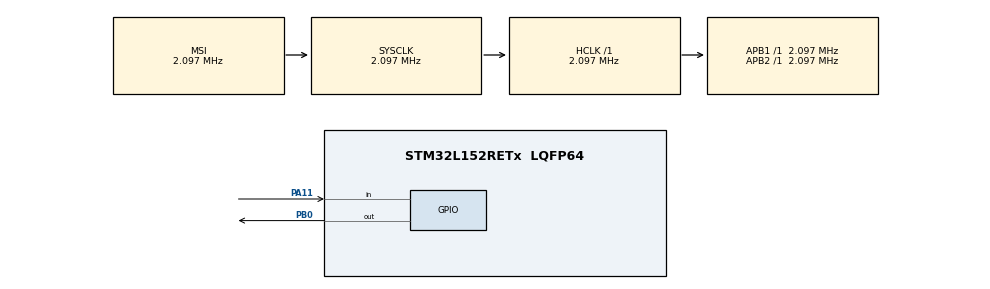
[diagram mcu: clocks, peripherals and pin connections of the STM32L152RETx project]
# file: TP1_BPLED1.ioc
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Mcu.Family=STM32L1
Mcu.Name=STM32L152RETx
Mcu.Package=LQFP64
NVIC.PriorityGroup=NVIC_PRIORITYGROUP_4
PA11.Signal=GPIO_Input
PB0.GPIO_ModeDefaultOutputPP=GPIO_MODE_OUTPUT_PP
PB0.Signal=GPIO_Output
ProjectManager.HeapSize=0x200
ProjectManager.StackSize=0x400
ProjectManager.TargetToolchain=STM32CubeIDE
RCC.AHBFreq_Value=2097000
RCC.APB1Freq_Value=2097000
RCC.APB2Freq_Value=2097000
RCC.HSE_VALUE=24000000
RCC.HSI_VALUE=16000000
RCC.LSE_VALUE=32768
RCC.MSI_VALUE=2097000
RCC.SYSCLKFreq_VALUE=2097000
RCC.VCOOutputFreq_Value=48000000
board=custom

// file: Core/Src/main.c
/* USER CODE BEGIN Header */
/**
  ******************************************************************************
  * @file           : main.c
  * @brief          : Main program body
  ******************************************************************************
  * @attention
  *
  * Copyright (c) 2025 STMicroelectronics.
  * All rights reserved.
  *
  * This software is licensed under terms that can be found in the LICENSE file
  * in the root directory of this software component.
  * If no LICENSE file comes with this software, it is provided AS-IS.
  *
  ******************************************************************************
  */
/* USER CODE END Header */
#include "main.h"

/* USER CODE BEGIN PD */

//#define V1
#define V2

/* USER CODE END PD */

void SystemClock_Config(void);
static void MX_GPIO_Init(void);
/* USER CODE BEGIN PFP */
void init_ports_LED(void);
void init_ports_BP(void);
void allume_LED(void);
void eteint_LED(void);
/* USER CODE END PFP */

/* USER CODE BEGIN 0 */
void init_ports_LED(void) {
	GPIOB->ODR |= 1<<0;
}

void init_ports_BP(void) {
	GPIOA->MODER &= ~(1<<11);
}

void allume_LED(void) {
	GPIOB->ODR |= (1<<0);
}

void eteint_LED(void) {
	GPIOB->ODR &= ~(1<<0);
}
/* USER CODE END 0 */

int main(void)
{

  /* MCU Configuration--------------------------------------------------------*/

  /* Reset of all peripherals, Initializes the Flash interface and the Systick. */
  HAL_Init();

  /* Configure the system clock */
  SystemClock_Config();

  /* Initialize all configured peripherals */
  MX_GPIO_Init();
  /* USER CODE BEGIN 2 */
  init_ports_LED();
  init_ports_BP();

  /* USER CODE END 2 */

  /* Infinite loop */
  while (1)
  {
#ifdef V1
	  if ((GPIOA->IDR & (1 << 11))  == 0) {
		  allume_LED();
		  HAL_Delay(1000);
	  } else {
		  eteint_LED();
		  HAL_Delay(1000);
	  }
#endif
#ifdef V2
	  uint32_t bit_state = (GPIOA->IDR >> 11) & 1;

	  GPIOB->BSRR = (1 << 16) | (bit_state << 0);
#endif

  }
}

void SystemClock_Config(void)
{
  RCC_OscInitTypeDef RCC_OscInitStruct = {0};
  RCC_ClkInitTypeDef RCC_ClkInitStruct = {0};

  /** Configure the main internal regulator output voltage
  */
  __HAL_PWR_VOLTAGESCALING_CONFIG(PWR_REGULATOR_VOLTAGE_SCALE1);

  /** Initializes the RCC Oscillators according to the specified parameters
  * in the RCC_OscInitTypeDef structure.
  */
  RCC_OscInitStruct.OscillatorType = RCC_OSCILLATORTYPE_MSI;
  RCC_OscInitStruct.MSIState = RCC_MSI_ON;
  RCC_OscInitStruct.MSICalibrationValue = 0;
  RCC_OscInitStruct.MSIClockRange = RCC_MSIRANGE_5;
  RCC_OscInitStruct.PLL.PLLState = RCC_PLL_NONE;
  if (HAL_RCC_OscConfig(&RCC_OscInitStruct) != HAL_OK)
  {
    Error_Handler();
  }

  /** Initializes the CPU, AHB and APB buses clocks
  */
  RCC_ClkInitStruct.ClockType = RCC_CLOCKTYPE_HCLK|RCC_CLOCKTYPE_SYSCLK
                              |RCC_CLOCKTYPE_PCLK1|RCC_CLOCKTYPE_PCLK2;
  RCC_ClkInitStruct.SYSCLKSource = RCC_SYSCLKSOURCE_MSI;
  RCC_ClkInitStruct.AHBCLKDivider = RCC_SYSCLK_DIV1;
  RCC_ClkInitStruct.APB1CLKDivider = RCC_HCLK_DIV1;
  RCC_ClkInitStruct.APB2CLKDivider = RCC_HCLK_DIV1;

  if (HAL_RCC_ClockConfig(&RCC_ClkInitStruct, FLASH_LATENCY_0) != HAL_OK)
  {
    Error_Handler();
  }
}

static void MX_GPIO_Init(void)
{
  GPIO_InitTypeDef GPIO_InitStruct = {0};

  /* GPIO Ports Clock Enable */
  __HAL_RCC_GPIOB_CLK_ENABLE();
  __HAL_RCC_GPIOA_CLK_ENABLE();

  /*Configure GPIO pin Output Level */
  HAL_GPIO_WritePin(GPIOB, GPIO_PIN_0, GPIO_PIN_RESET);

  /*Configure GPIO pin : PB0 */
  GPIO_InitStruct.Pin = GPIO_PIN_0;
  GPIO_InitStruct.Mode = GPIO_MODE_OUTPUT_PP;
  GPIO_InitStruct.Pull = GPIO_NOPULL;
  GPIO_InitStruct.Speed = GPIO_SPEED_FREQ_LOW;
  HAL_GPIO_Init(GPIOB, &GPIO_InitStruct);

  /*Configure GPIO pin : PA11 */
  GPIO_InitStruct.Pin = GPIO_PIN_11;
  GPIO_InitStruct.Mode = GPIO_MODE_INPUT;
  GPIO_InitStruct.Pull = GPIO_NOPULL;
  HAL_GPIO_Init(GPIOA, &GPIO_InitStruct);

}

void Error_Handler(void)
{
  __disable_irq();
  while (1)
  {
  }
}
